# RN821X_RN721X_SOC_V3 register map
File version: v1.0.4
CPU: CM0 r0p0, little endian, no MPU, no FPU, 3 interrupt priority bits
Registers are 32-bit, read-write, reset 0x0 unless marked. A register's access mark holds for its fields unless they carry their own. Offsets are from the block's base; [hi:lo] are bit positions; {n}, {i} and the like mark numbered series; 'fields as' and 'values as' point back to an identical list.

## GPIO
Base 0x50000000
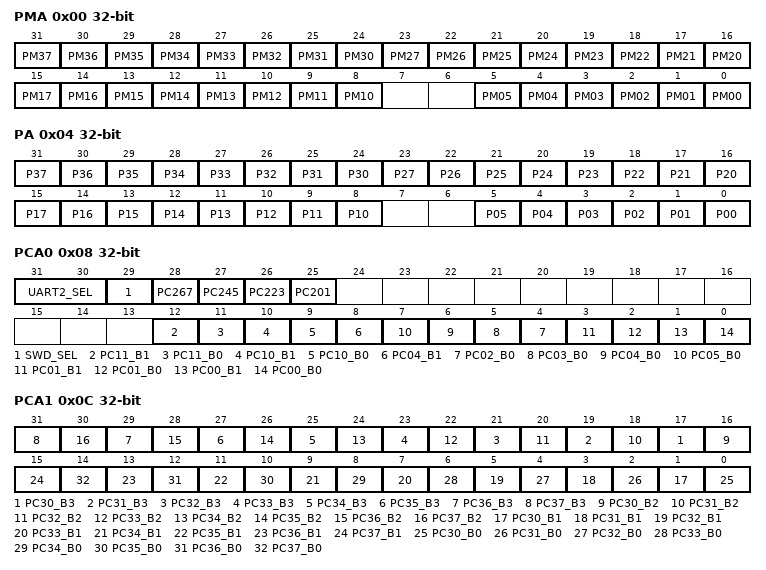
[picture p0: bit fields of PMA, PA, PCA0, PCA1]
0x00 PMA — port A mode register
  [all] fields
    0=OUT (use as output mode); 1=IN (use as input mode)
  [31] PM37 — P37 input(1)/output(0) mode state bi
  [30] PM36 — P36 input(1)/output(0) mode state bit
  [n-6] PM{n} (n=30..35) — P{n} input(1)/output(0) mode selection bit
  [n-4] PM{n} (n=20..27) — P{n} input(1)/output(0) mode selection bit
  [n-2] PM{n} (n=10..17) — P{n} input(1)/output(0) mode selection bit
  [n] PM{n:02} (n=0..5) — P{n:02} input(1)/output(0) mode selection bit
0x04 PA — port A data register
  [31] P37 ro — port A P37 data bit
  [30] P36 ro — port A P36 data bit
  [n-6] P{n} (n=30..35) — port A P{n} data bit
  [n-4] P{n} (n=20..27) — port A P{n} data bit
  [n-2] P{n} (n=10..17) — port A P{n} data bit
  [n] P{n:02} (n=0..5) — port A P{n:02} data bit
0x08 PCA0 — port A mode config register 0
  [31:30] UART2_SEL — UART2 selection bits
  [29] SWD_SEL — SWD selection bit
  [28] PC267 — P26 and P27 mode cfg bit
  [27] PC245 — P24 and P25 mode cfg bit
  [26] PC223 — P22 and P23 mode cfg bit
  [25] PC201 — P20 and P21 mode cfg bit
  [12] PC11_B1 — PC11 mode cfg bit1, detail info please read manual PCA0.PC11(PCA0[12:11])
  [11] PC11_B0 — PC11 mode cfg bit0, detail info please read manual PCA0.PC11(PCA0[12:11])
  [10] PC10_B1 — PC10 mode cfg bit1, detail info please read manual PCA0.PC10(PCA0[10:9])
  [9] PC10_B0 — PC10 mode cfg bit0, detail info please read manual PCA0.PC10(PCA0[10:9])
  [8] PC04_B1 — PC04 mode cfg bit1, detail info please read manual PCA0.PC04(PCA0[6])
  [n+2] PC{n:02}_B0 (n=2..5) — PC{n:02} mode cfg bit0, detail info please read manual PCA0.PC{n:02}(PCA0[{n+2}])
  [3] PC01_B1 — PC01 mode cfg bit1, detail info please read manual PCA0.PC01(PCA0[3:2])
  [2] PC01_B0 — PC01 mode cfg bit0, detail info please read manual PCA0.PC01(PCA0[3:2])
  [1] PC00_B1 — PC00 mode cfg bit1, detail info please read manual PCA0.PC00(PCA0[1:0])
  [0] PC00_B0 — PC00 mode cfg bit0, detail info please read manual PCA0.PC00(PCA0[1:0])
0x0C PCA1 — port A mode config register 1
  [2n-43] PC{n}_B3 (n=30..37) — PC{n} mode cfg bit3, detail info please read manual PCA1.PC{n}(PCA1[{2n-59}:{2n-60}])
  [2n-44] PC{n}_B2 (n=30..37) — PC{n} mode cfg bit2, detail info please read manual PCA1.PC{n}(PCA1[{2n-59}:{2n-60}])
  [2n-59] PC{n}_B1 (n=30..37) — PC{n} mode cfg bit1, detail info please read manual PCA1.PC{n}(PCA1[{2n-59}:{2n-60}])
  [2n-60] PC{n}_B0 (n=30..37) — PC{n} mode cfg bit0, detail info please read manual PCA1.PC{n}(PCA1[{2n-59}:{2n-60}])
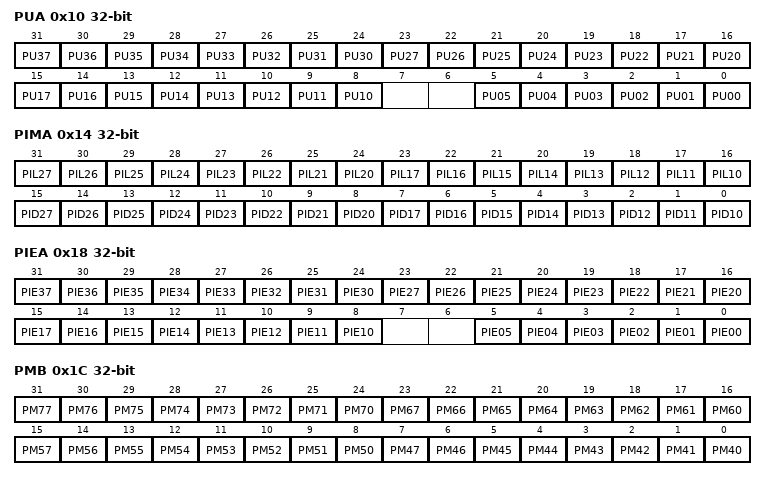
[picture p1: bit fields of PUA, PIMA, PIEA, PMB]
0x10 PUA — port A pull-up config register
  [all] fields
    0=NUL (do not pull-up); 1=PU (pull-up)
  [31] PU37 — P37 pull-down enable bit
  [30] PU36 — P36 pull-down enable bit
  [n-6] PU{n} (n=30..35) — P{n} pull up cfg bit (=0 do not pull up, =1 pull up)
  [n-4] PU{n} (n=20..27) — P{n} pull up cfg bit (=0 do not pull up, =1 pull up)
  [n-2] PU{n} (n=10..17) — P{n} pull up cfg bit (=0 do not pull up, =1 pull up)
  [n] PU{n:02} (n=0..5) — P{n:02} pull up cfg bit (=0 do not pull up, =1 pull up)
0x14 PIMA — port A input config register
  [n+4] PIL{n} (n=20..27) — P{n} input cfg bit
    0=CMOS (select as CMOS input mode, Vil=0.3VCC Vih = 0.7VCC); 1=TTL (select as TTL input mode, Vil=0.16VCC Vih = 0.4VCC)
  [n+6] PIL{n} (n=10..17) — P{n} input cfg bit
    values as PIL20
  [n-12] PID{n} (n=20..27) — P{n} output mode cfg bit
    0=NORM (select as normal output mode); 1=NCH (select as N channel open drain output)
  [n-10] PID{n} (n=10..17) — P{n} output mode cfg bit
    values as PID20
0x18 PIEA — port A input enable register
  [n-6] PIE{n} (n=30..37) — P{n} input disbale bit (=1 disable input, =0 enable input)
  [n-4] PIE{n} (n=20..27) — P{n} input disbale bit (=1 disable input, =0 enable input)
  [n-2] PIE{n} (n=10..17) — P{n} input disbale bit (=1 disable input, =0 enable input)
  [n] PIE{n:02} (n=1..5) — P{n:02} input disbale bit (=1 disable input, =0 enable input)
  [0] PIE00 — P00 input disbale bit (=1 disable input, =0 enable input)
    1=DIS (disable input); 0=EN (enable input)
0x1C PMB — port B mode register
  [n-46] PM{n} (n=70..77) — P{n} input/output cfg bit (=0 output mode, =1 input mode)
  [n-44] PM{n} (n=60..67) — P{n} input/output cfg bit (=0 output mode, =1 input mode)
  [n-42] PM{n} (n=50..57) — P{n} input/output cfg bit (=0 output mode, =1 input mode)
  [n-40] PM{n} (n=41..47) — P{n} input/output cfg bit (=0 output mode, =1 input mode)
  [0] PM40 — P40 input/output cfg bit (=0 output mode, =1 input mode)
    0=OUT (use as output mode); 1=IN (use as input mode)
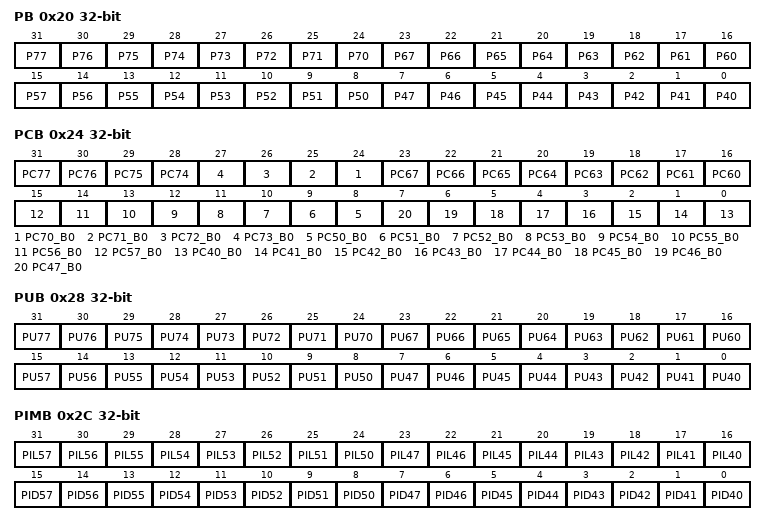
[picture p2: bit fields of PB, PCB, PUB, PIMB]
0x20 PB — port B data register
  [n-46] P{n} (n=70..77) — port B P{n} data bit
  [n-44] P{n} (n=60..67) — port B P{n} data bit
  [n-42] P{n} (n=50..57) — port B P{n} data bit
  [n-40] P{n} (n=40..47) — port B P{n} data bit
0x24 PCB — port B mode config register
  [n-46] PC{n} (n=74..77) — P{n} mode cfg bit
  [n-46] PC{n}_B0 (n=70..73) — P{n} mode cfg bit0, detail info please read manual PCB[{n-46}]
  [n-44] PC{n} (n=60..67) — P{n} mode cfg bit
  [n-42] PC{n}_B0 (n=50..57) — PC{n} mode cfg bit0, detail info please read manual PCB[{n-42}]
  [n-40] PC{n}_B0 (n=40..47) — PC{n} mode cfg bit0, detail info please read manual PCB[{n-40}]
0x28 PUB — port B pull-up/down config register
  [n-46] PU{n} (n=70..77) — P{n} pull-down enable bit (=1 enable pull-down, =0 do not enable pul down)
    0=NUL (do not pull-down); 1=DOWN (pull-down)
  [n-44] PU{n} (n=60..67) — P{n} pull-down enable bit (=1 enable pull-down, =0 do not enable pul down)
    0=NUL (do not pull-down); 1=DOWN (pull-down)
  [n-42] PU{n} (n=50..57) — P{n} pull-up enable bit (=1 enable pull-up, =0 do not enable pull up)
    0=NUL (do not pull-up); 1=UP (pull-up)
  [n-40] PU{n} (n=40..47) — P{n} pull-up enable bit (=1 enable pull-up, =0 do not enable pull up)
    0=NUL (do not pull-up); 1=UP (pull-up)
0x2C PIMB — port B input config register
  [n-26] PIL{n} (n=50..57) — P{n} input mode cfg bit
    values as PIMA.PIL20
  [n-24] PIL{n} (n=40..47) — P{n} input mode cfg bit
    values as PIMA.PIL20
  [n-42] PID{n} (n=50..57) — P{n} output mode cfg bit
    values as PIMA.PID20
  [n-40] PID{n} (n=40..47) — P{n} output mode cfg bit
    values as PIMA.PID20
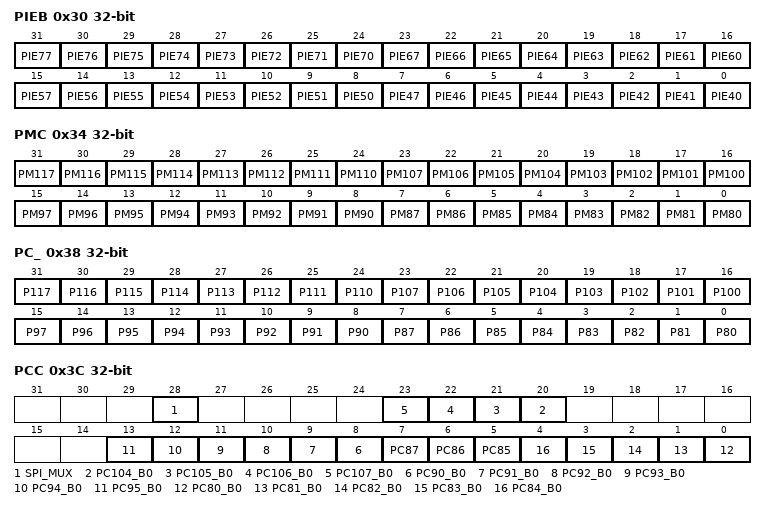
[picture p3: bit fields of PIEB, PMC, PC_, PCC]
0x30 PIEB — port B input enable register
  [all] fields
    1=DIS (do not use as input); 0=EN (use as input)
  [n-46] PIE{n} (n=70..77) — P{n} input disable bit (=1 disable input, =0 enable input)
  [n-44] PIE{n} (n=60..67) — P{n} input disable bit (=1 disable input, =0 enable input)
  [n-42] PIE{n} (n=50..57) — P{n} input disable bit (=1 disable input, =0 enable input)
  [n-40] PIE{n} (n=40..47) — P{n} input disable bit (=1 disable input, =0 enable input)
0x34 PMC — port C mode register
  [all] fields
    0=OUT (use as output mode); 1=IN (use as input mode)
  [n-86] PM{n} (n=110..117) — P{n} input/output cfg bit (=0 output mode, =1 input mode)
  [n-84] PM{n} (n=100..107) — P{n} input/output cfg bit (=0 output mode, =1 input mode)
  [n-82] PM{n} (n=90..97) — P{n} input/output cfg bit (=0 output mode, =1 input mode)
  [n-80] PM{n} (n=80..87) — P{n} input/output cfg bit (=0 output mode, =1 input mode)
0x38 PC_ — port C data register
  [n-86] P{n} (n=110..117) — port C P{n} data bit
  [n-84] P{n} (n=100..107) — port C P{n} data bit
  [n-82] P{n} (n=90..97) — port C P{n} data bit
  [n-80] P{n} (n=80..87) — port C P{n} data bit
0x3C PCC — port C mode config register
  [28] SPI_MUX — SPI0 pin defination bit
  [n-84] PC{n}_B0 (n=104..107) — PC{n} mode cfg bit0, detail info please read manual PCC[{n-84}]
  [n-82] PC{n}_B0 (n=90..95) — PC{n} mode cfg bit0, detail info please read manual PCC[{n-82}]
  [7] PC87 — PC87 mode cfg bit
  [6] PC86 — PC86 mode cfg bit
  [5] PC85 — PC85 mode cfg bit
  [n-80] PC{n}_B0 (n=80..84) — PC{n} mode cfg bit0, detail info please read manual PCC[{n-80}]
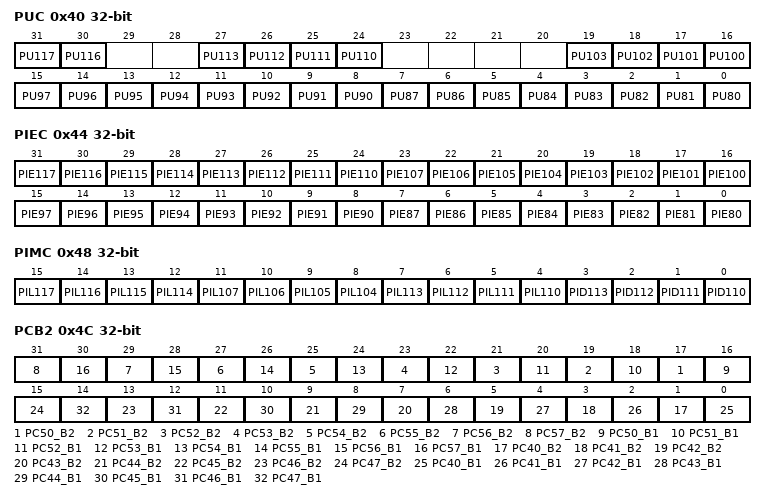
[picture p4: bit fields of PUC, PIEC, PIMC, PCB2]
0x40 PUC — port C pull-up/down config register
  [31] PU117 — P117 pull up enable bit(=1 enable pull-up ,=0 do not enable pull-up)
    0=NUL (do not pull-up); 1=UP (pull-up)
  [30] PU116 — P116 pull up enable bit(=1 enable pull-up ,=0 do not enable pull-up)
    0=NUL (do not pull-up); 1=UP (pull-up)
  [n-86] PU{n} (n=110..113) — P{n} pull up enable bit(=1 enable pull-up ,=0 do not enable pull-up)
    0=NUL (do not pull-up); 1=UP (pull-up)
  [n-84] PU{n} (n=100..103) — P{n} pull down enable bit(=1 enable pull-down ,=0 do not enable pull-down)
    0=NUL (do not pull-up); 1=UP (pull-up)
  [n-82] PU{n} (n=90..97) — P{n} pull down enable bit(=1 enable pull-down ,=0 do not enable pull-down)
    0=NUL (do not pull-down); 1=DOWN (pull-down)
  [n-80] PU{n} (n=80..87) — P{n} pull down enable bit(=1 enable pull-down ,=0 do not enable pull-down)
    0=NUL (do not pull-down); 1=DOWN (pull-down)
0x44 PIEC — port C input enable register
  [all] fields
    1=DIS (disable input); 0=EN (enable input)
  [n-86] PIE{n} (n=110..117) — P{n} input disable bit(=1 disable input, =0 enable input)
  [n-84] PIE{n} (n=100..107) — P{n} input disable bit(=1 disable input, =0 enable input)
  [n-82] PIE{n} (n=90..97) — P{n} input disable bit(=1 disable input, =0 enable input)
  [n-80] PIE{n} (n=80..87) — P{n} input disable bit(=1 disable input, =0 enable input)
0x48 PIMC — port C input config register
  [n-102] PIL{n} (n=114..117) — P{n} input mode cfg bit
    values as PIMA.PIL20
  [n-96] PIL{n} (n=104..107) — P{n} input mode cfg bit
    values as PIMA.PIL20
  [n-106] PIL{n} (n=110..113) — P{n} input mode cfg bit
    values as PIMA.PIL20
  [n-110] PID{n} (n=110..113) — P{n} output mode cfg bit
    values as PIMA.PID20
0x4C PCB2 — port B mode config register 2
  [2n-83] PC{n}_B2 (n=50..57) — PC{n} mode cfg bit2, detail info please read manual
  [2n-84] PC{n}_B1 (n=50..57) — PC{n} mode cfg bit1, detail info please read manual
  [2n-79] PC{n}_B2 (n=40..47) — PC{n} mode cfg bit2, detail info please read manual
  [2n-80] PC{n}_B1 (n=40..47) — PC{n} mode cfg bit1, detail info please read manual
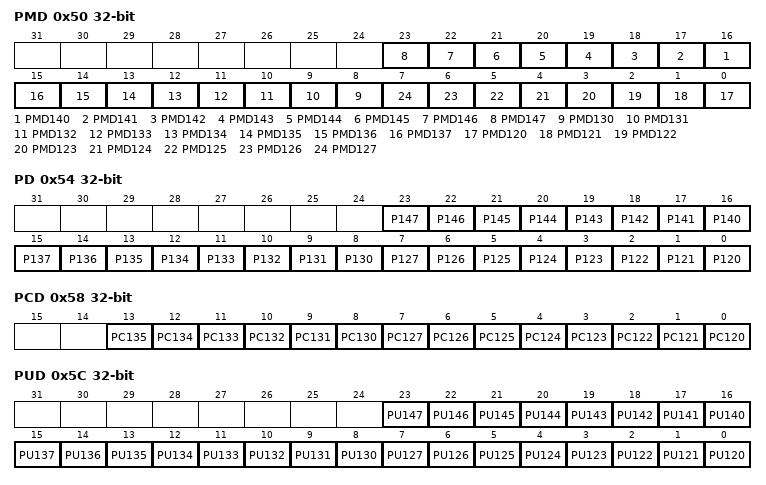
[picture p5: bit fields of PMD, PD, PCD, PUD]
0x50 PMD — port D mode register
  [all] fields
    0=OUT (use as output mode); 1=IN (use as input mode)
  [n-124] PMD{n} (n=140..147) — P{n} input/output mode cfg bit (=0 output mode, =1 input mode)
  [n-122] PMD{n} (n=130..137) — P{n} input/output mode cfg bit (=0 output mode, =1 input mode)
  [n-120] PMD{n} (n=120..127) — P{n} input/output mode cfg bit (=0 output mode, =1 input mode)
0x54 PD — port D data register
  [n-124] P{n} (n=140..147) — port D P{n} data bit
  [n-122] P{n} (n=130..137) — port D P{n} data bit
  [n-120] P{n} (n=120..127) — port D P{n} data bit
0x58 PCD — port D mode config register 0
  [13] PC135 — P135 mode cfg bit
  [12] PC134 — P134 mode cfg bit
  [11] PC133 — P133 mode cfg bit (=0 select as IO, =1 reserved)
  [10] PC132 — P132 mode cfg bit
  [9] PC131 — P131 mode cfg bit
  [8] PC130 — P130 mode cfg bit
  [n-120] PC{n} (n=120..127) — P{n} mode cfg bit
0x5C PUD — port D pull-up/down config register
  [23] PU147 — P147 pull up enable bit(=1 enable pull-up ,=0 do not enable pull-up)
    0=NUL (do not pull-up); 1=UP (pull-up)
  [22] PU146 — P146 pull up enable bit(=1 enable pull-up ,=0 do not enable pull-up)
    0=NUL (do not pull-up); 1=UP (pull-up)
  [21] PU145 — P145 pull down enable bit
    0=NUL (do not pull-down); 1=DOWN (pull-down)
  [n-124] PU{n} (n=140..144) — P{n} pull up enable bit(=1 enable pull-up ,=0 do not enable pull-up)
    0=NUL (do not pull-up); 1=UP (pull-up)
  [n-122] PU{n} (n=130..137) — P{n} pull down enable bit(=1 enable pull-down ,=0 do not enable pull-down)
    0=NUL (do not pull-down); 1=DOWN (pull-down)
  [n-120] PU{n} (n=120..127) — P{n} pull down enable bit(=1 enable pull-down ,=0 do not enable pull-down)
    0=NUL (do not pull-down); 1=DOWN (pull-down)
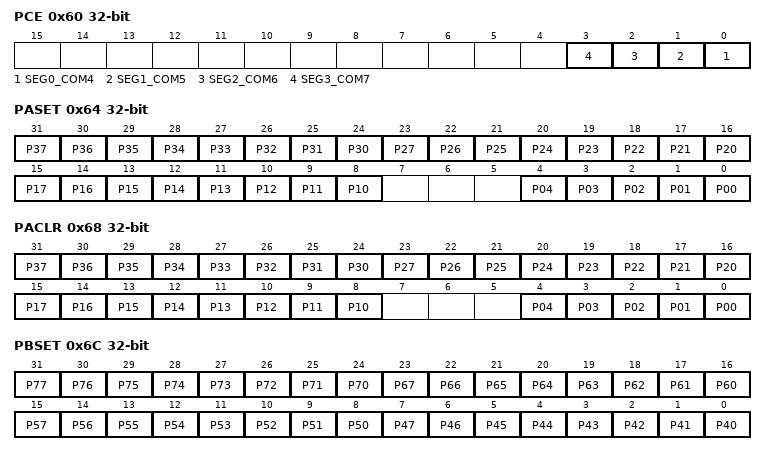
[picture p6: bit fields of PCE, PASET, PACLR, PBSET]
0x60 PCE — SEGCOM mode selection register
  [all] fields
    0=SEG (select as SEG); 1=COM (select as COM)
  [n] SEG{n}_COM{n+4} (n=0..3) — SEG{n}_COM{n+4} mode selection bit
0x64 PASET — port A state set register
  [all] fields
    0=NUL (no effection); 1=HIGH (set as high level)
  [n-6] P{n} (n=30..37) — PA P{n} state set bit
  [n-4] P{n} (n=20..27) — PA P{n} state set bit
  [n-2] P{n} (n=10..17) — PA P{n} state set bit
  [n] P{n:02} (n=0..4) — PA P{n:02} state set bit
0x68 PACLR — port A state clean register
  [all] fields
    0=NUL (no effection); 1=CLR (clean pin state, set low level output)
  [n-6] P{n} (n=30..37) — PA P{n} state clean bit
  [n-4] P{n} (n=20..27) — PA P{n} state clean bit
  [n-2] P{n} (n=10..17) — PA P{n} state clean bit
  [n] P{n:02} (n=0..4) — PA P{n:02} state clean bit
0x6C PBSET — port B state set register
  [all] fields
    0=NUL (no effection); 1=HIGH (set as high level)
  [n-46] P{n} (n=70..77) — PB P{n} state set bit
  [n-44] P{n} (n=60..67) — PB P{n} state set bit
  [n-42] P{n} (n=50..57) — PB P{n} state set bit
  [n-40] P{n} (n=40..47) — PB P{n} state set bit
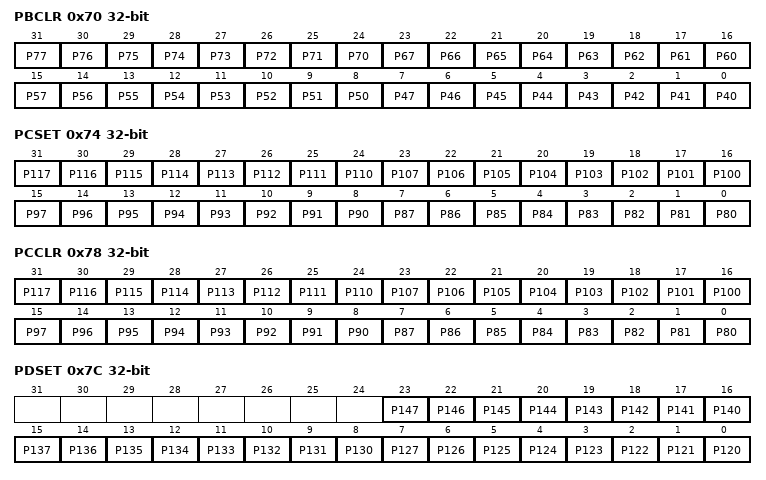
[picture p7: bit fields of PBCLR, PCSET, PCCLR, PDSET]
0x70 PBCLR — port B state clean register
  [all] fields
    values as the fields of PACLR
  [n-46] P{n} (n=70..77) — PB P{n} state clean bit
  [n-44] P{n} (n=60..67) — PB P{n} state clean bit
  [n-42] P{n} (n=50..57) — PB P{n} state clean bit
  [n-40] P{n} (n=40..47) — PB P{n} state clean bit
0x74 PCSET — port C state set register
  [all] fields
    0=NUL (no effection); 1=HIGH (set as high level)
  [n-86] P{n} (n=110..117) — PC P{n} state set bit
  [n-84] P{n} (n=100..107) — PC P{n} state set bit
  [n-82] P{n} (n=90..97) — PC P{n} state set bit
  [n-80] P{n} (n=80..87) — PC P{n} state set bit
0x78 PCCLR — port C state clean register
  [all] fields
    values as the fields of PACLR
  [n-86] P{n} (n=110..117) — PC P{n} state clean bit
  [n-84] P{n} (n=100..107) — PC P{n} state clean bit
  [n-82] P{n} (n=90..97) — PC P{n} state clean bit
  [n-80] P{n} (n=80..87) — PC P{n} state clean bit
0x7C PDSET — port D state set register
  [all] fields
    0=NUL (no effection); 1=HIGH (set as high level)
  [n-124] P{n} (n=140..147) — PD P{n} state set bit
  [n-122] P{n} (n=130..137) — PD P{n} state set bit
  [n-120] P{n} (n=120..127) — PD P{n} state set bit
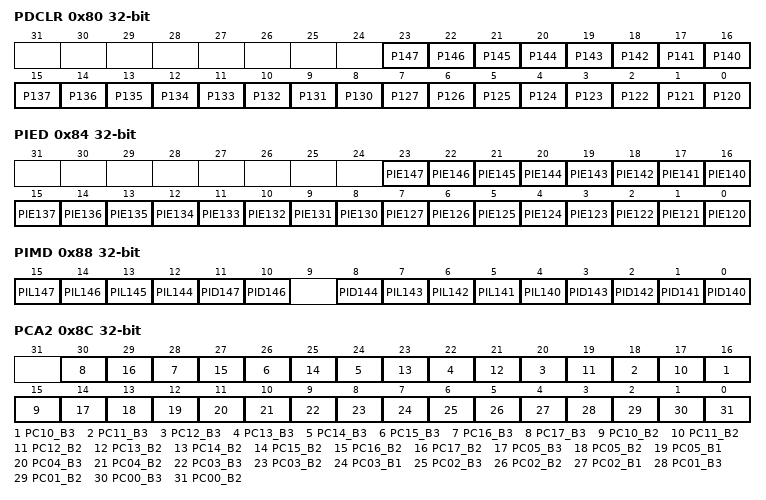
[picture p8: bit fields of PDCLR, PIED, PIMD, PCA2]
0x80 PDCLR — port D state clean register
  [all] fields
    values as the fields of PACLR
  [n-124] P{n} (n=140..147) — PD P{n} state clean bit
  [n-122] P{n} (n=130..137) — PD P{n} state clean bit
  [n-120] P{n} (n=120..127) — PD P{n} state clean bit
0x84 PIED — port D input enable register
  [all] fields
    1=DIS (disable input); 0=EN (enable input)
  [n-124] PIE{n} (n=140..147) — P{n} input disable bit
  [n-122] PIE{n} (n=130..137) — P{n} input disable bit
  [n-120] PIE{n} (n=120..127) — P{n} input disable bit
0x88 PIMD — port D input config register
  [n-132] PIL{n} (n=144..147) — P{n} input mode cfg bit
  [11] PID147 — P147 output mode cfg bit
  [10] PID146 — P146 output mode cfg bit
  [8] PID144 — P144 output mode cfg bit
  [7] PIL143 — P143 input mode cfg bit
  [6] PIL142 — P142 input mode cfg bit
    values as PIMA.PIL20
  [5] PIL141 — P141 input mode cfg bit
    values as PIMA.PIL20
  [4] PIL140 — P140 input mode cfg bit
    values as PIMA.PIL20
  [3] PID143 — P143 output mode cfg bit
    0=NORM (select as normal output mode)
  [2] PID142 — P142 output mode cfg bit
    values as PIMA.PID20
  [1] PID141 — P141 output mode cfg bit
    values as PIMA.PID20
  [0] PID140 — P140 output mode cfg bit
    values as PIMA.PID20
0x8C PCA2 — port A mode config register 2
  [2n-4] PC{n}_B3 (n=10..17) — PC{n} mode cfg bit3, detail info please read manual PCA0.PC{n}(PCA0[{2n-10}:{2n-11}])
  [2n-5] PC{n}_B2 (n=10..17) — PC{n} mode cfg bit2, detail info please read manual PCA0.PC{n}(PCA0[{2n-10}:{2n-11}])
  [14] PC05_B3 — PC05 mode cfg bit3, detail info please read manual PCA0.PC05(PCA0[7])
  [13] PC05_B2 — PC05 mode cfg bit2, detail info please read manual PCA0.PC05(PCA0[7])
  [12] PC05_B1 — PC05 mode cfg bit1, detail info please read manual PCA0.PC05(PCA0[7])
  [11] PC04_B3 — PC04 mode cfg bit3, detail info please read manual PCA0.PC04(PCA0[6])
  [10] PC04_B2 — PC04 mode cfg bit2, detail info please read manual PCA0.PC04(PCA0[6])
  [9] PC03_B3 — PC03 mode cfg bit3, detail info please read manual PCA0.PC03(PCA0[5])
  [8] PC03_B2 — PC03 mode cfg bit2, detail info please read manual PCA0.PC03(PCA0[5])
  [7] PC03_B1 — PC03 mode cfg bit1, detail info please read manual PCA0.PC03(PCA0[5])
  [6] PC02_B3 — PC02 mode cfg bit3, detail info please read manual PCA0.PC02(PCA0[4])
  [5] PC02_B2 — PC02 mode cfg bit2, detail info please read manual PCA0.PC02(PCA0[4])
  [4] PC02_B1 — PC02 mode cfg bit1, detail info please read manual PCA0.PC02(PCA0[4])
  [3] PC01_B3 — PC01 mode cfg bit3, detail info please read manual PCA0.PC01(PCA0[3:2])
  [2] PC01_B2 — PC01 mode cfg bit2, detail info please read manual PCA0.PC01(PCA0[3:2])
  [1] PC00_B3 — PC00 mode cfg bit3, detail info please read manual PCA0.PC00(PCA0[1:0])
  [0] PC00_B2 — PC00 mode cfg bit2, detail info please read manual PCA0.PC00(PCA0[1:0])
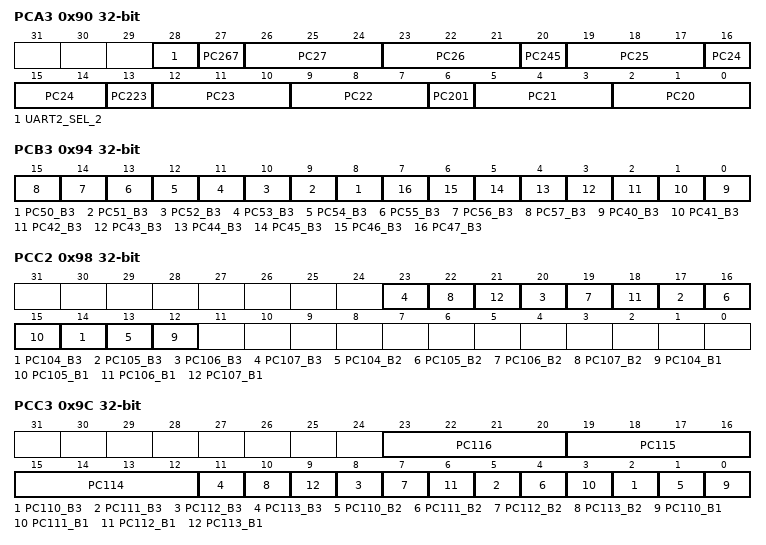
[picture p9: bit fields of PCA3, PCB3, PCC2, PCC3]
0x90 PCA3 — port A mode config register 3
  [28] UART2_SEL_2 — UART2 second selection bit, detail info please read manual PCA0[31:30]
  [27] PC267 — PC267 second mode cfg bit
  [26:24] PC27 — PC27 second mode cfg bits
  [23:21] PC26 — PC26 second mode cfg bits
  [20] PC245 — PC245 second mode cfg bit
  [19:17] PC25 — PC25 second mode cfg bits
  [16:14] PC24 — PC24 second mode cfg bits
  [13] PC223 — PC223 second mode cfg bit
  [12:10] PC23 — PC23 second mode cfg bits
  [9:7] PC22 — PC22 second mode cfg bits
  [6] PC201 — PC201 second mode cfg bit
  [5:3] PC21 — PC21 second mode cfg bits
  [2:0] PC20 — PC20 second mode cfg bits
0x94 PCB3 — port B mode config register 3
  [n-42] PC{n}_B3 (n=50..57) — PC{n} mode cfg bit3, detail info please read manual PC{n}[{n-42}]
  [n-40] PC{n}_B3 (n=40..47) — PC{n} mode cfg bit3, detail info please read manual PC{n}[{n-40}]
0x98 PCC2 — port C mode config register 2
  [3n-298] PC{n}_B3 (n=104..107) — PC{n} mode cfg bit3, detail info please read manual PCC[{n-84}]
  [3n-299] PC{n}_B2 (n=104..107) — PC{n} mode cfg bit2, detail info please read manual PCC[{n-84}]
  [3n-300] PC{n}_B1 (n=104..107) — PC{n} mode cfg bit1, detail info please read manual PCC[{n-84}]
0x9C PCC3 — port C mode config register 3
  [23:20] PC116 — PC116 mode cfg bits
  [19:16] PC115 — PC115 mode cfg bits
  [15:12] PC114 — PC114 mode cfg bits
  [3n-328] PC{n}_B3 (n=110..113) — PC{n} mode cfg bit3, detail info please read manual PCC[{n-86}]
  [3n-329] PC{n}_B2 (n=110..113) — PC{n} mode cfg bit2, detail info please read manual PCC[{n-86}]
  [3n-330] PC{n}_B1 (n=110..113) — PC{n} mode cfg bit1, detail info please read manual PCC[{n-86}]
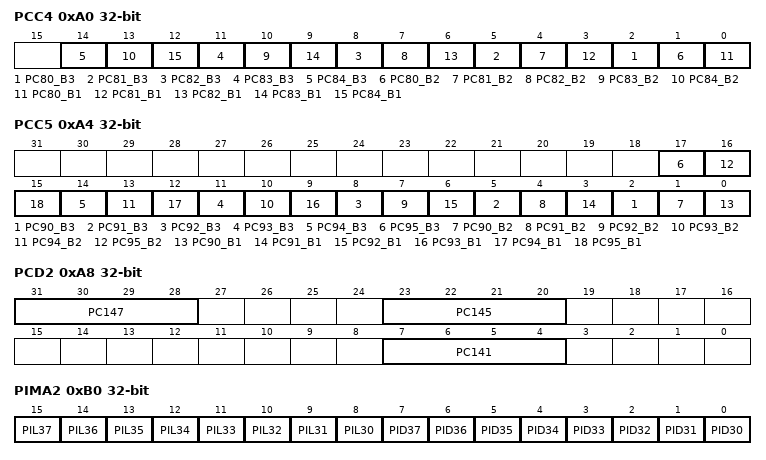
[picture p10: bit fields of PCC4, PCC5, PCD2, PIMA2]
0xA0 PCC4 — port C mode config register 4
  [3n-238] PC{n}_B3 (n=80..84) — PC{n} mode cfg bit3, detail info please read manual PCC[{n-80}]
  [3n-239] PC{n}_B2 (n=80..84) — PC{n} mode cfg bit2, detail info please read manual PCC[{n-80}]
  [3n-240] PC{n}_B1 (n=80..84) — PC{n} mode cfg bit1, detail info please read manual PCC[{n-80}]
0xA4 PCC5 — port C mode config register 5
  [3n-268] PC{n}_B3 (n=90..95) — PC{n} mode cfg bit3, detail info please read manual PCC[{n-82}]
  [3n-269] PC{n}_B2 (n=90..95) — PC{n} mode cfg bit2, detail info please read manual PCC[{n-82}]
  [3n-270] PC{n}_B1 (n=90..95) — PC{n} mode cfg bit1, detail info please read manual PCC[{n-82}]
0xA8 PCD2 — port D mode config register 2
  [31:28] PC147 — PC147 mode cfg bits
  [23:20] PC145 — PC145 mode cfg bits
  [7:4] PC141 — PC141 mode cfg bits
0xB0 PIMA2 — port A input config register 2
  [n-22] PIL{n} (n=30..37) — P{n} input mode cfg bit
    values as PIMA.PIL20
  [n-30] PID{n} (n=30..37) — P{n} output mode cfg bit
    values as PIMA.PID20
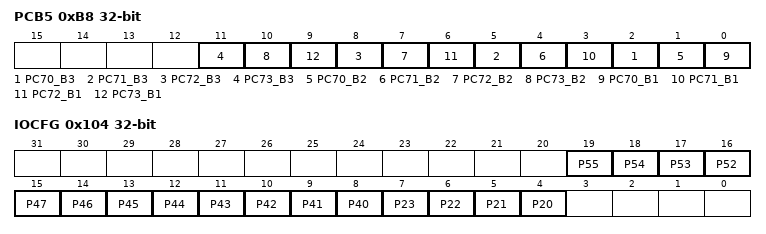
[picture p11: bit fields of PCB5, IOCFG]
0xB8 PCB5 — port B mode config register 5
  [3n-208] PC{n}_B3 (n=70..73) — P{n} mode cfg bit3, detail info please read manual PCB[{n-46}]
  [3n-209] PC{n}_B2 (n=70..73) — P{n} mode cfg bit2, detail info please read manual PCB[{n-46}]
  [3n-210] PC{n}_B1 (n=70..73) — P{n} mode cfg bit1, detail info please read manual PCB[{n-46}]
0x104 IOCFG — IO congfig register
  [all] fields
    1=FAST (select as slew rate fast mode, have driving capability of 3mA); 0=SLOW (select as slew rate slow mode, have driving capability of 1.5mA)
  [n-36] P{n} (n=52..55) — P{n} IO driving capability select bit
  [n-32] P{n} (n=40..47) — P{n} IO driving capability select bit
  [n-16] P{n} (n=20..23) — P{n} IO driving capability select bit
